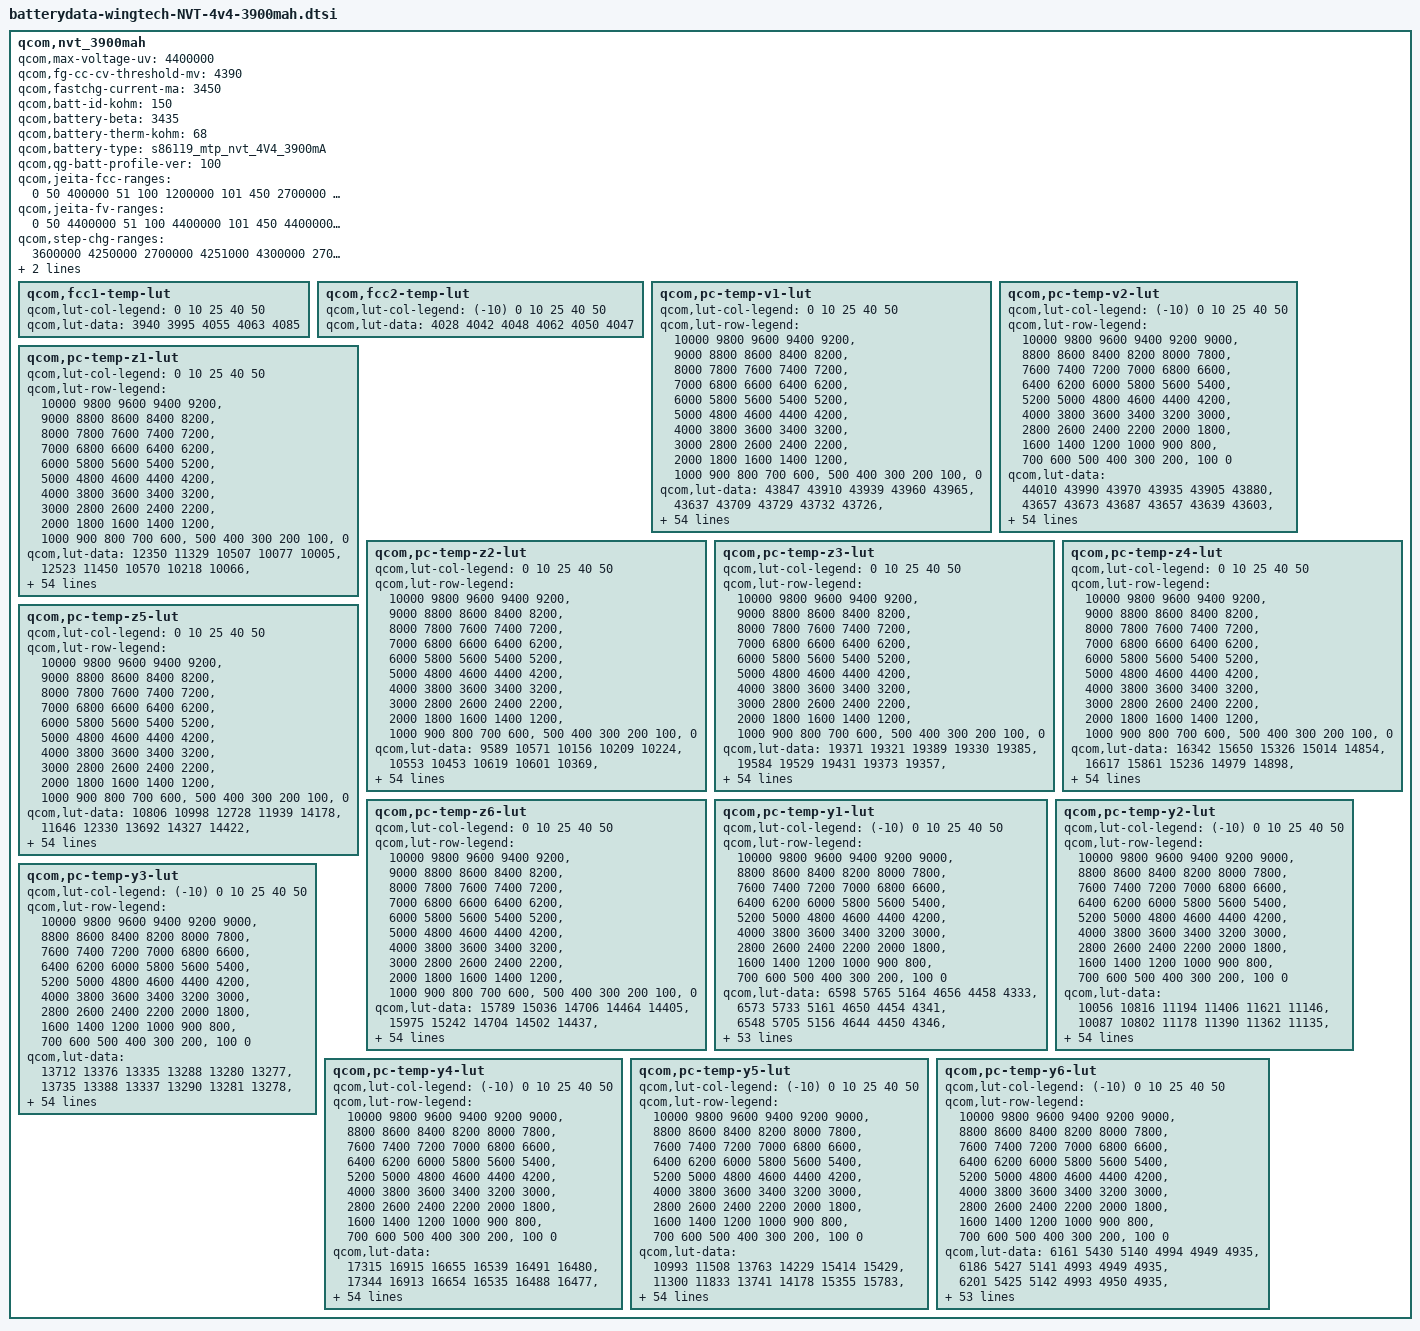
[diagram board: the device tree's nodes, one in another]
/* Copyright (c) 2018, The Linux Foundation. All rights reserved.
 *
 * This program is free software; you can redistribute it and/or modify
 * it under the terms of the GNU General Public License version 2 and
 * only version 2 as published by the Free Software Foundation.
 *
 * This program is distributed in the hope that it will be useful,
 * but WITHOUT ANY WARRANTY; without even the implied warranty of
 * MERCHANTABILITY or FITNESS FOR A PARTICULAR PURPOSE.  See the
 * GNU General Public License for more details.
 */

qcom,nvt_3900mah {
	/* nvt_wConn_3900mAh_Fresh_averaged_MasterSlave_Feb7th2018 */
	qcom,max-voltage-uv = <4400000>;
	qcom,fg-cc-cv-threshold-mv = <4390>;
	qcom,fastchg-current-ma = <3450>;
	qcom,batt-id-kohm = <150>;
	qcom,battery-beta = <3435>;
	qcom,battery-therm-kohm = <68>;
	qcom,battery-type =
		"s86119_mtp_nvt_4V4_3900mA";
	qcom,qg-batt-profile-ver = <100>;
	//+Bug 439935 gudi.wt,MODIFIY,20190628,S86119AA1 set follow to batt spec
	qcom,jeita-fcc-ranges = <0   50  400000
				51  100  1200000
				101  450 2700000
				451  600 1400000>;
	qcom,jeita-fv-ranges = <0   50  4400000
				51 100  4400000
				101 450 4400000
				451 600  4100000>;
	qcom,step-chg-ranges = <3600000  4250000  2700000
				4251000  4300000  2700000
				4301000  4400000  2700000>;

	/* COOL = 5 DegC, WARM = 45 DegC */
	qcom,jeita-soft-thresholds = <0x2E1E 0x123E>;
	/* COLD = 0 DegC, HOT = 55 DegC */
	qcom,jeita-hard-thresholds = <0x3480 0x0F3B>;
	//+Bug 439935 gudi.wt,MODIFIY,20190628,S86119AA1 set follow to batt spec
	qcom,fcc1-temp-lut {
		qcom,lut-col-legend = <0 10 25 40 50>;
		qcom,lut-data = <3940 3995 4055 4063 4085>;
	};

	qcom,fcc2-temp-lut {
		qcom,lut-col-legend = <(-10) 0 10 25 40 50>;
		qcom,lut-data = <4028 4042 4048 4062 4050 4047>;
	};

	qcom,pc-temp-v1-lut {
		qcom,lut-col-legend = <0 10 25 40 50>;
		qcom,lut-row-legend = <10000 9800 9600 9400 9200>,
			<9000 8800 8600 8400 8200>,
			<8000 7800 7600 7400 7200>,
			<7000 6800 6600 6400 6200>,
			<6000 5800 5600 5400 5200>,
			<5000 4800 4600 4400 4200>,
			<4000 3800 3600 3400 3200>,
			<3000 2800 2600 2400 2200>,
			<2000 1800 1600 1400 1200>,
			<1000 900 800 700 600>,
			<500 400 300 200 100>,
			<0>;
		qcom,lut-data = <43847 43910 43939 43960 43965>,
			<43637 43709 43729 43732 43726>,
			<43385 43471 43501 43515 43502>,
			<43131 43225 43264 43291 43283>,
			<42890 42981 43028 43058 43054>,
			<42654 42741 42790 42824 42822>,
			<42421 42505 42552 42590 42587>,
			<42189 42271 42315 42355 42351>,
			<41964 42041 42081 42121 42117>,
			<41745 41814 41849 41889 41885>,
			<41533 41589 41621 41660 41658>,
			<41334 41374 41398 41436 41437>,
			<41152 41181 41185 41218 41218>,
			<40956 40992 40988 41009 41007>,
			<40719 40777 40786 40802 40798>,
			<40474 40537 40567 40593 40588>,
			<40253 40318 40347 40388 40381>,
			<40046 40131 40155 40200 40193>,
			<39874 39961 39979 40025 40022>,
			<39743 39808 39814 39856 39856>,
			<39625 39670 39669 39702 39701>,
			<39498 39518 39512 39538 39540>,
			<39367 39347 39291 39300 39325>,
			<39231 39166 39028 39013 39048>,
			<39086 38959 38829 38830 38850>,
			<38939 38746 38674 38723 38735>,
			<38794 38604 38558 38632 38639>,
			<38651 38510 38479 38540 38543>,
			<38545 38439 38417 38454 38452>,
			<38472 38384 38356 38370 38361>,
			<38413 38339 38300 38288 38271>,
			<38363 38295 38244 38214 38189>,
			<38319 38254 38188 38148 38119>,
			<38280 38213 38134 38086 38056>,
			<38247 38172 38085 38028 38001>,
			<38214 38131 38040 37972 37952>,
			<38180 38093 37997 37919 37895>,
			<38144 38056 37958 37873 37825>,
			<38093 38005 37909 37818 37745>,
			<38012 37917 37823 37730 37655>,
			<37910 37805 37708 37617 37551>,
			<37783 37685 37583 37504 37430>,
			<37631 37547 37443 37382 37289>,
			<37470 37386 37287 37218 37137>,
			<37328 37239 37147 37068 37002>,
			<37230 37152 37066 36971 36924>,
			<37201 37126 37045 36956 36897>,
			<37174 37114 37031 36943 36892>,
			<37148 37093 37011 36932 36871>,
			<37095 37043 36941 36844 36767>,
			<36841 36791 36666 36582 36468>,
			<36394 36349 36217 36129 36013>,
			<35801 35769 35627 35601 35425>,
			<34988 34972 34817 34781 34622>,
			<33711 33731 33549 33515 33376>,
			<30000 30000 30000 30000 30000>;
	};

	qcom,pc-temp-v2-lut {
		qcom,lut-col-legend = <(-10) 0 10 25 40 50>;
		qcom,lut-row-legend = <10000 9800 9600 9400 9200 9000>,
			<8800 8600 8400 8200 8000 7800>,
			<7600 7400 7200 7000 6800 6600>,
			<6400 6200 6000 5800 5600 5400>,
			<5200 5000 4800 4600 4400 4200>,
			<4000 3800 3600 3400 3200 3000>,
			<2800 2600 2400 2200 2000 1800>,
			<1600 1400 1200 1000 900 800>,
			<700 600 500 400 300 200>,
			<100 0>;
		qcom,lut-data = <44010 43990 43970 43935 43905 43880>,
			<43657 43673 43687 43657 43639 43603>,
			<43328 43377 43418 43392 43382 43340>,
			<43029 43105 43162 43141 43138 43092>,
			<42754 42854 42919 42904 42905 42859>,
			<42489 42609 42679 42668 42672 42627>,
			<42227 42367 42442 42431 42437 42392>,
			<41973 42130 42207 42194 42202 42157>,
			<41725 41902 41976 41963 41970 41927>,
			<41485 41679 41747 41733 41741 41698>,
			<41270 41458 41522 41506 41515 41472>,
			<41085 41240 41299 41280 41293 41251>,
			<40900 41030 41085 41063 41076 41033>,
			<40704 40846 40896 40864 40870 40823>,
			<40490 40665 40712 40670 40667 40618>,
			<40205 40418 40496 40459 40461 40417>,
			<39805 40082 40246 40234 40252 40221>,
			<39500 39792 40004 40033 40059 40036>,
			<39353 39583 39782 39869 39892 39868>,
			<39236 39403 39571 39706 39729 39702>,
			<39086 39235 39371 39504 39547 39524>,
			<38916 39081 39182 39280 39352 39336>,
			<38752 38931 39009 39074 39151 39139>,
			<38588 38779 38846 38878 38934 38922>,
			<38440 38634 38699 38710 38743 38731>,
			<38322 38504 38570 38578 38606 38594>,
			<38222 38382 38452 38465 38492 38482>,
			<38139 38271 38347 38362 38388 38377>,
			<38071 38168 38253 38268 38293 38282>,
			<38010 38075 38164 38180 38206 38193>,
			<37952 37990 38079 38100 38127 38113>,
			<37897 37916 37999 38026 38054 38039>,
			<37841 37864 37922 37959 37986 37972>,
			<37782 37824 37848 37896 37923 37909>,
			<37725 37785 37793 37837 37854 37836>,
			<37669 37745 37756 37781 37774 37738>,
			<37613 37704 37720 37721 37688 37635>,
			<37554 37660 37679 37650 37593 37531>,
			<37492 37610 37635 37573 37495 37429>,
			<37430 37551 37572 37496 37409 37339>,
			<37367 37476 37479 37415 37334 37261>,
			<37306 37377 37376 37314 37238 37164>,
			<37239 37246 37256 37193 37117 37045>,
			<37145 37114 37107 37047 36980 36905>,
			<37055 36997 36976 36923 36857 36803>,
			<36947 36925 36926 36890 36828 36780>,
			<36899 36892 36902 36875 36814 36750>,
			<36847 36859 36880 36857 36795 36747>,
			<36764 36811 36844 36812 36756 36698>,
			<36640 36705 36751 36693 36643 36574>,
			<36405 36432 36461 36347 36318 36214>,
			<36008 35945 35955 35822 35827 35702>,
			<35418 35282 35293 35132 35165 35046>,
			<34556 34348 34377 34166 34287 34117>,
			<33099 32790 32996 32738 33050 32805>,
			<29158 30446 29275 28278 29363 29146>;
	};

	qcom,pc-temp-z1-lut {
		qcom,lut-col-legend = <0 10 25 40 50>;
		qcom,lut-row-legend = <10000 9800 9600 9400 9200>,
			<9000 8800 8600 8400 8200>,
			<8000 7800 7600 7400 7200>,
			<7000 6800 6600 6400 6200>,
			<6000 5800 5600 5400 5200>,
			<5000 4800 4600 4400 4200>,
			<4000 3800 3600 3400 3200>,
			<3000 2800 2600 2400 2200>,
			<2000 1800 1600 1400 1200>,
			<1000 900 800 700 600>,
			<500 400 300 200 100>,
			<0>;
		qcom,lut-data = <12350 11329 10507 10077 10005>,
			<12523 11450 10570 10218 10066>,
			<12574 11459 10576 10225 10073>,
			<12594 11473 10571 10224 10071>,
			<12583 11476 10564 10223 10070>,
			<12563 11457 10557 10220 10070>,
			<12548 11436 10549 10215 10067>,
			<12529 11425 10543 10213 10064>,
			<12515 11416 10539 10212 10071>,
			<12524 11414 10535 10212 10082>,
			<12538 11414 10533 10211 10079>,
			<12531 11414 10531 10209 10065>,
			<12510 11416 10531 10207 10059>,
			<12490 11419 10532 10205 10061>,
			<12463 11410 10532 10203 10066>,
			<12437 11374 10525 10202 10085>,
			<12423 11353 10516 10201 10115>,
			<12398 11349 10515 10200 10117>,
			<12380 11347 10515 10200 10084>,
			<12389 11349 10516 10201 10064>,
			<12401 11353 10518 10202 10066>,
			<12390 11355 10520 10203 10072>,
			<12366 11358 10522 10205 10083>,
			<12356 11363 10523 10208 10104>,
			<12359 11370 10525 10210 10111>,
			<12366 11380 10527 10212 10100>,
			<12384 11390 10530 10213 10091>,
			<12421 11406 10537 10216 10094>,
			<12433 11416 10544 10219 10099>,
			<12414 11408 10546 10222 10098>,
			<12395 11394 10546 10225 10088>,
			<12405 11392 10546 10228 10084>,
			<12435 11397 10551 10228 10091>,
			<12446 11403 10557 10229 10100>,
			<12437 11412 10563 10231 10100>,
			<12428 11421 10568 10235 10096>,
			<12430 11422 10574 10237 10096>,
			<12435 11423 10579 10238 10098>,
			<12436 11424 10584 10240 10100>,
			<12424 11423 10589 10276 10101>,
			<12416 11422 10595 10330 10101>,
			<12446 11431 10599 10320 10103>,
			<12481 11448 10603 10258 10105>,
			<12442 11465 10614 10305 10107>,
			<12388 11474 10622 10360 10110>,
			<12370 11446 10620 10278 10112>,
			<12355 11466 10614 10271 10139>,
			<12354 11447 10616 10316 10126>,
			<12414 11438 10617 10279 10110>,
			<12340 11477 10619 10325 10114>,
			<12419 11464 10631 10281 10116>,
			<12407 11501 10641 10347 10123>,
			<12407 11505 10655 10333 10131>,
			<12468 11544 10684 10374 10145>,
			<12468 11544 10684 10374 10145>,
			<12468 11544 10684 10374 10145>;
	};

	qcom,pc-temp-z2-lut {
		qcom,lut-col-legend = <0 10 25 40 50>;
		qcom,lut-row-legend = <10000 9800 9600 9400 9200>,
			<9000 8800 8600 8400 8200>,
			<8000 7800 7600 7400 7200>,
			<7000 6800 6600 6400 6200>,
			<6000 5800 5600 5400 5200>,
			<5000 4800 4600 4400 4200>,
			<4000 3800 3600 3400 3200>,
			<3000 2800 2600 2400 2200>,
			<2000 1800 1600 1400 1200>,
			<1000 900 800 700 600>,
			<500 400 300 200 100>,
			<0>;
		qcom,lut-data = <9589 10571 10156 10209 10224>,
			<10553 10453 10619 10601 10369>,
			<10385 10412 10597 10658 10566>,
			<10262 10358 10553 10628 10557>,
			<10259 10324 10493 10579 10498>,
			<10257 10302 10459 10567 10475>,
			<10259 10290 10435 10565 10477>,
			<10271 10288 10429 10567 10482>,
			<10285 10287 10462 10573 10497>,
			<10295 10288 10501 10580 10518>,
			<10305 10296 10520 10594 10500>,
			<10332 10309 10535 10613 10422>,
			<10394 10351 10551 10621 10392>,
			<10426 10403 10570 10623 10422>,
			<10361 10406 10580 10624 10440>,
			<10274 10388 10567 10619 10445>,
			<10270 10380 10550 10608 10454>,
			<10311 10423 10548 10596 10448>,
			<10366 10473 10550 10570 10376>,
			<10472 10474 10555 10550 10338>,
			<10570 10464 10585 10546 10372>,
			<10557 10460 10636 10568 10433>,
			<10472 10464 10724 10697 10547>,
			<10417 10471 10835 10928 10753>,
			<10395 10483 10854 10960 10823>,
			<10383 10498 10809 10701 10608>,
			<10385 10502 10754 10510 10405>,
			<10392 10500 10695 10553 10431>,
			<10399 10499 10645 10636 10519>,
			<10405 10501 10666 10717 10616>,
			<10412 10508 10765 10881 10752>,
			<10421 10518 10813 10947 10816>,
			<10432 10533 10818 10825 10710>,
			<10445 10540 10820 10697 10557>,
			<10460 10539 10788 10703 10510>,
			<10477 10537 10717 10741 10518>,
			<10503 10540 10700 10779 10580>,
			<10536 10550 10713 10827 10810>,
			<10566 10564 10735 10867 10980>,
			<10593 10584 10796 10896 10960>,
			<10624 10609 10870 10915 10917>,
			<10667 10636 10881 10919 10892>,
			<10738 10671 10873 10940 10872>,
			<10955 10738 10893 11031 10816>,
			<11280 10967 10987 11103 10707>,
			<11381 11436 11144 10782 10627>,
			<10891 11588 11094 10741 10570>,
			<10873 11637 11063 10722 10690>,
			<10876 11891 11118 11007 10736>,
			<10917 11547 11211 10889 10675>,
			<10931 11771 11325 11573 10558>,
			<10619 11757 11302 10939 10316>,
			<10625 11425 11226 11470 10305>,
			<10335 10897 11033 10507 10251>,
			<10335 10897 11033 10507 10251>,
			<10335 10897 11033 10507 10251>;
	};

	qcom,pc-temp-z3-lut {
		qcom,lut-col-legend = <0 10 25 40 50>;
		qcom,lut-row-legend = <10000 9800 9600 9400 9200>,
			<9000 8800 8600 8400 8200>,
			<8000 7800 7600 7400 7200>,
			<7000 6800 6600 6400 6200>,
			<6000 5800 5600 5400 5200>,
			<5000 4800 4600 4400 4200>,
			<4000 3800 3600 3400 3200>,
			<3000 2800 2600 2400 2200>,
			<2000 1800 1600 1400 1200>,
			<1000 900 800 700 600>,
			<500 400 300 200 100>,
			<0>;
		qcom,lut-data = <19371 19321 19389 19330 19385>,
			<19584 19529 19431 19373 19357>,
			<19829 19667 19526 19436 19403>,
			<19963 19743 19568 19472 19445>,
			<19983 19779 19587 19493 19460>,
			<19994 19800 19589 19494 19462>,
			<19994 19811 19588 19483 19454>,
			<19990 19813 19585 19472 19446>,
			<19983 19814 19570 19463 19446>,
			<19963 19813 19550 19455 19447>,
			<19935 19806 19534 19445 19437>,
			<19907 19793 19519 19435 19408>,
			<19867 19756 19505 19425 19394>,
			<19847 19713 19490 19417 19393>,
			<19945 19708 19483 19410 19393>,
			<20074 19712 19485 19404 19392>,
			<20083 19713 19490 19399 19392>,
			<20046 19689 19487 19393 19389>,
			<19995 19660 19474 19387 19364>,
			<19881 19656 19465 19380 19347>,
			<19769 19655 19459 19372 19346>,
			<19779 19656 19455 19366 19346>,
			<19868 19679 19472 19379 19355>,
			<19941 19706 19508 19411 19379>,
			<19988 19719 19516 19417 19388>,
			<20022 19729 19506 19393 19365>,
			<20035 19731 19491 19369 19338>,
			<20043 19725 19474 19357 19326>,
			<20044 19717 19456 19349 19318>,
			<20032 19706 19445 19354 19325>,
			<20013 19694 19435 19382 19374>,
			<19997 19684 19433 19400 19404>,
			<19980 19674 19458 19407 19400>,
			<19961 19669 19481 19411 19393>,
			<19939 19672 19482 19408 19381>,
			<19914 19675 19481 19401 19359>,
			<19885 19672 19478 19394 19352>,
			<19852 19661 19469 19388 19361>,
			<19830 19652 19460 19384 19367>,
			<19813 19648 19452 19389 19365>,
			<19796 19643 19446 19397 19361>,
			<19774 19630 19444 19387 19362>,
			<19737 19608 19443 19350 19367>,
			<19653 19583 19437 19353 19365>,
			<19481 19531 19419 19359 19352>,
			<19353 19440 19386 19344 19337>,
			<19320 19415 19380 19344 19333>,
			<19316 19320 19365 19334 19310>,
			<19314 19308 19362 19310 19308>,
			<19311 19297 19347 19327 19316>,
			<19320 19332 19322 19292 19320>,
			<19314 19333 19310 19331 19334>,
			<19326 19321 19316 19293 19333>,
			<19333 19313 19311 19340 19336>,
			<19333 19313 19311 19340 19336>,
			<19333 19313 19311 19340 19336>;
	};

	qcom,pc-temp-z4-lut {
		qcom,lut-col-legend = <0 10 25 40 50>;
		qcom,lut-row-legend = <10000 9800 9600 9400 9200>,
			<9000 8800 8600 8400 8200>,
			<8000 7800 7600 7400 7200>,
			<7000 6800 6600 6400 6200>,
			<6000 5800 5600 5400 5200>,
			<5000 4800 4600 4400 4200>,
			<4000 3800 3600 3400 3200>,
			<3000 2800 2600 2400 2200>,
			<2000 1800 1600 1400 1200>,
			<1000 900 800 700 600>,
			<500 400 300 200 100>,
			<0>;
		qcom,lut-data = <16342 15650 15326 15014 14854>,
			<16617 15861 15236 14979 14898>,
			<16518 15839 15335 15046 14877>,
			<16385 15659 15272 15018 14935>,
			<16227 15508 15158 14943 14876>,
			<16049 15388 15089 14891 14832>,
			<15906 15286 15039 14848 14801>,
			<15779 15205 14992 14826 14783>,
			<15691 15137 14941 14818 14780>,
			<15643 15082 14904 14813 14777>,
			<15607 15035 14894 14807 14775>,
			<15570 14998 14888 14800 14773>,
			<15521 14964 14879 14793 14771>,
			<15461 14937 14865 14783 14753>,
			<15332 14931 14849 14773 14737>,
			<15203 14929 14834 14765 14739>,
			<15191 14928 14818 14757 14742>,
			<15205 14928 14803 14747 14739>,
			<15211 14928 14787 14733 14731>,
			<15242 14911 14776 14727 14724>,
			<15279 14866 14765 14729 14717>,
			<15237 14835 14757 14733 14712>,
			<15090 14816 14776 14762 14730>,
			<14981 14806 14828 14830 14805>,
			<14923 14835 14870 14868 14854>,
			<14888 14902 14909 14887 14876>,
			<14894 14925 14928 14895 14888>,
			<14915 14929 14927 14892 14890>,
			<14925 14930 14925 14885 14885>,
			<14926 14923 14920 14867 14863>,
			<14927 14908 14906 14818 14782>,
			<14923 14893 14887 14777 14728>,
			<14914 14878 14842 14746 14718>,
			<14906 14861 14798 14726 14713>,
			<14901 14840 14778 14724 14713>,
			<14897 14820 14764 14723 14715>,
			<14897 14808 14759 14723 14716>,
			<14902 14799 14757 14726 14718>,
			<14903 14796 14756 14731 14720>,
			<14889 14794 14770 14757 14728>,
			<14877 14794 14790 14792 14740>,
			<14874 14793 14790 14792 14739>,
			<14875 14792 14780 14772 14729>,
			<14914 14789 14776 14784 14731>,
			<14945 14773 14764 14793 14734>,
			<14969 14765 14725 14732 14705>,
			<14995 14785 14717 14713 14711>,
			<14991 14881 14713 14714 14702>,
			<14987 14888 14697 14699 14668>,
			<14983 14896 14718 14713 14672>,
			<14988 14875 14785 14758 14703>,
			<15010 14885 14811 14759 14696>,
			<15007 14909 14809 14750 14698>,
			<15020 14929 14822 14734 14696>,
			<15020 14929 14822 14734 14696>,
			<15020 14929 14822 14734 14696>;
	};

	qcom,pc-temp-z5-lut {
		qcom,lut-col-legend = <0 10 25 40 50>;
		qcom,lut-row-legend = <10000 9800 9600 9400 9200>,
			<9000 8800 8600 8400 8200>,
			<8000 7800 7600 7400 7200>,
			<7000 6800 6600 6400 6200>,
			<6000 5800 5600 5400 5200>,
			<5000 4800 4600 4400 4200>,
			<4000 3800 3600 3400 3200>,
			<3000 2800 2600 2400 2200>,
			<2000 1800 1600 1400 1200>,
			<1000 900 800 700 600>,
			<500 400 300 200 100>,
			<0>;
		qcom,lut-data = <10806 10998 12728 11939 14178>,
			<11646 12330 13692 14327 14422>,
			<12442 13290 14476 15377 16936>,
			<12922 13882 14876 15857 16779>,
			<13057 14353 15220 16882 17794>,
			<13146 14736 15411 17476 18632>,
			<13270 15109 15540 17900 19328>,
			<13477 15542 15756 18058 19697>,
			<13590 16005 16360 17928 19582>,
			<13497 16507 16856 17734 19310>,
			<13377 17141 16753 17550 18845>,
			<13353 17534 16473 17291 17690>,
			<13311 17612 16389 17221 17320>,
			<13436 17671 16403 17274 18721>,
			<15411 18037 16444 17327 19875>,
			<17756 18957 16868 17356 19824>,
			<17898 19370 17569 17394 19699>,
			<17356 18135 18079 17591 19089>,
			<16754 16688 18780 18202 17702>,
			<15692 16921 19424 18602 16933>,
			<14686 18449 20567 18648 17373>,
			<15055 20978 22708 18854 18522>,
			<17128 28139 31386 23602 21655>,
			<20088 35878 45887 33994 28548>,
			<25891 40453 48473 36008 30908>,
			<32633 43967 41165 27497 24444>,
			<37727 44260 33355 19881 17460>,
			<42200 39970 27930 17383 15423>,
			<43440 35014 23506 15891 14245>,
			<40999 31484 20907 15961 14626>,
			<37635 28467 19022 17225 18304>,
			<35337 26657 18541 18845 21520>,
			<33310 25311 20596 21135 23066>,
			<31282 24789 23526 23614 24084>,
			<29194 25974 25958 25761 23804>,
			<27179 27538 28180 27689 22157>,
			<25022 27583 28620 28068 22090>,
			<22864 27090 28117 27286 25307>,
			<22011 26913 27402 26039 27757>,
			<22340 28089 25940 23750 25329>,
			<22776 29335 24187 20812 21092>,
			<22493 28068 23507 18811 20474>,
			<21530 25083 23098 17245 21027>,
			<19009 24057 22034 17268 20180>,
			<15964 23419 21397 17595 18117>,
			<13972 19974 21297 22901 17679>,
			<13115 17339 20079 21157 18804>,
			<12998 13243 18091 19247 16348>,
			<12975 12808 18590 16465 17382>,
			<12988 12647 16821 20918 17667>,
			<13210 13642 13935 13711 14742>,
			<12918 13442 12983 13661 15010>,
			<12967 12913 12951 12368 14621>,
			<12819 12554 12603 18035 14421>,
			<12819 12554 12603 18035 14421>,
			<12819 12554 12603 18035 14421>;
	};

	qcom,pc-temp-z6-lut {
		qcom,lut-col-legend = <0 10 25 40 50>;
		qcom,lut-row-legend = <10000 9800 9600 9400 9200>,
			<9000 8800 8600 8400 8200>,
			<8000 7800 7600 7400 7200>,
			<7000 6800 6600 6400 6200>,
			<6000 5800 5600 5400 5200>,
			<5000 4800 4600 4400 4200>,
			<4000 3800 3600 3400 3200>,
			<3000 2800 2600 2400 2200>,
			<2000 1800 1600 1400 1200>,
			<1000 900 800 700 600>,
			<500 400 300 200 100>,
			<0>;
		qcom,lut-data = <15789 15036 14706 14464 14405>,
			<15975 15242 14704 14502 14437>,
			<16026 15270 14795 14566 14452>,
			<16043 15237 14782 14566 14496>,
			<15994 15200 14750 14551 14483>,
			<15899 15154 14725 14534 14468>,
			<15825 15109 14701 14509 14450>,
			<15757 15073 14675 14491 14437>,
			<15704 15040 14645 14483 14437>,
			<15671 15012 14619 14477 14438>,
			<15644 14988 14606 14468 14432>,
			<15603 14964 14596 14459 14414>,
			<15545 14929 14584 14451 14402>,
			<15512 14897 14571 14442 14394>,
			<15508 14886 14559 14433 14388>,
			<15507 14882 14553 14426 14389>,
			<15500 14877 14547 14419 14396>,
			<15482 14865 14538 14411 14392>,
			<15456 14851 14524 14401 14370>,
			<15410 14834 14514 14395 14354>,
			<15362 14816 14505 14391 14351>,
			<15340 14811 14501 14389 14350>,
			<15326 14815 14518 14409 14364>,
			<15322 14822 14560 14459 14415>,
			<15323 14844 14580 14473 14436>,
			<15327 14881 14590 14468 14431>,
			<15336 14892 14594 14462 14423>,
			<15354 14892 14588 14456 14418>,
			<15360 14891 14577 14449 14413>,
			<15355 14883 14568 14443 14407>,
			<15347 14869 14557 14437 14397>,
			<15337 14857 14549 14431 14389>,
			<15323 14848 14543 14422 14384>,
			<15311 14839 14537 14415 14380>,
			<15298 14832 14531 14410 14373>,
			<15286 14825 14525 14407 14361>,
			<15278 14818 14520 14405 14358>,
			<15270 14812 14514 14403 14362>,
			<15260 14808 14511 14402 14366>,
			<15248 14806 14515 14420 14369>,
			<15234 14804 14519 14449 14371>,
			<15221 14800 14519 14442 14371>,
			<15203 14794 14515 14404 14370>,
			<15176 14783 14511 14418 14369>,
			<15103 14753 14499 14434 14365>,
			<15053 14701 14465 14385 14344>,
			<15036 14697 14458 14376 14349>,
			<15035 14692 14448 14379 14330>,
			<15033 14690 14440 14353 14312>,
			<15032 14692 14442 14376 14318>,
			<15054 14705 14458 14371 14336>,
			<15057 14716 14467 14403 14343>,
			<15072 14729 14472 14378 14345>,
			<15112 14746 14483 14402 14350>,
			<15112 14746 14483 14402 14350>,
			<15112 14746 14483 14402 14350>;
	};

	qcom,pc-temp-y1-lut {
		qcom,lut-col-legend = <(-10) 0 10 25 40 50>;
		qcom,lut-row-legend = <10000 9800 9600 9400 9200 9000>,
			<8800 8600 8400 8200 8000 7800>,
			<7600 7400 7200 7000 6800 6600>,
			<6400 6200 6000 5800 5600 5400>,
			<5200 5000 4800 4600 4400 4200>,
			<4000 3800 3600 3400 3200 3000>,
			<2800 2600 2400 2200 2000 1800>,
			<1600 1400 1200 1000 900 800>,
			<700 600 500 400 300 200>,
			<100 0>;
		qcom,lut-data = <6598 5765 5164 4656 4458 4333>,
			<6573 5733 5161 4650 4454 4341>,
			<6548 5705 5156 4644 4450 4346>,
			<6524 5682 5148 4639 4445 4350>,
			<6505 5667 5141 4634 4441 4351>,
			<6496 5663 5136 4630 4439 4351>,
			<6508 5671 5130 4628 4438 4348>,
			<6524 5681 5125 4625 4438 4345>,
			<6516 5688 5120 4622 4437 4346>,
			<6496 5696 5110 4619 4435 4348>,
			<6492 5695 5105 4616 4433 4349>,
			<6507 5664 5099 4614 4431 4345>,
			<6518 5640 5093 4612 4429 4342>,
			<6522 5651 5092 4610 4431 4343>,
			<6533 5669 5091 4609 4434 4344>,
			<6533 5668 5090 4610 4433 4346>,
			<6511 5647 5087 4612 4427 4347>,
			<6500 5635 5085 4614 4425 4348>,
			<6540 5656 5088 4612 4427 4346>,
			<6588 5684 5091 4610 4429 4345>,
			<6575 5686 5091 4611 4430 4345>,
			<6514 5672 5092 4613 4431 4347>,
			<6489 5664 5095 4615 4432 4348>,
			<6498 5661 5104 4618 4434 4349>,
			<6506 5659 5110 4621 4434 4350>,
			<6505 5656 5105 4622 4435 4351>,
			<6500 5651 5096 4624 4436 4353>,
			<6493 5651 5096 4627 4436 4354>,
			<6480 5649 5105 4635 4437 4358>,
			<6469 5647 5110 4639 4439 4360>,
			<6456 5644 5110 4640 4441 4360>,
			<6442 5645 5110 4640 4444 4360>,
			<6453 5658 5118 4642 4447 4362>,
			<6494 5677 5139 4646 4450 4365>,
			<6510 5684 5146 4652 4452 4367>,
			<6488 5664 5136 4660 4454 4370>,
			<6461 5645 5127 4667 4456 4372>,
			<6446 5648 5131 4668 4457 4373>,
			<6433 5660 5140 4670 4458 4374>,
			<6432 5673 5146 4673 4459 4375>,
			<6468 5689 5151 4677 4460 4376>,
			<6484 5681 5158 4677 4461 4377>,
			<6443 5646 5175 4676 4463 4379>,
			<6443 5691 5162 4681 4467 4380>,
			<6450 5676 5177 4691 4467 4397>,
			<6517 5697 5188 4698 4469 4385>,
			<6446 5728 5200 4693 4469 4414>,
			<6461 5710 5196 4697 4472 4398>,
			<6512 5687 5203 4700 4473 4385>,
			<6492 5696 5216 4706 4473 4386>,
			<6493 5676 5214 4701 4474 4390>,
			<6472 5702 5201 4712 4528 4420>,
			<6503 5698 5247 4738 4489 4400>,
			<6603 5705 5251 4751 4547 4413>,
			<6603 5705 5251 4751 4547 4413>,
			<6603 5705 5251 4751 4547 4413>;
	};

	qcom,pc-temp-y2-lut {
		qcom,lut-col-legend = <(-10) 0 10 25 40 50>;
		qcom,lut-row-legend = <10000 9800 9600 9400 9200 9000>,
			<8800 8600 8400 8200 8000 7800>,
			<7600 7400 7200 7000 6800 6600>,
			<6400 6200 6000 5800 5600 5400>,
			<5200 5000 4800 4600 4400 4200>,
			<4000 3800 3600 3400 3200 3000>,
			<2800 2600 2400 2200 2000 1800>,
			<1600 1400 1200 1000 900 800>,
			<700 600 500 400 300 200>,
			<100 0>;
		qcom,lut-data = <10056 10816 11194 11406 11621 11146>,
			<10087 10802 11178 11390 11362 11135>,
			<10119 10779 11147 11374 11183 11111>,
			<10148 10755 11111 11359 11070 11085>,
			<10168 10737 11084 11344 11007 11064>,
			<10175 10730 11075 11330 10984 11058>,
			<10169 10729 11076 11317 11044 11059>,
			<10161 10730 11078 11304 11113 11060>,
			<10200 10736 11079 11283 11133 11068>,
			<10319 10748 11081 11259 11175 11085>,
			<10417 10748 11080 11258 11190 11092>,
			<10497 10715 11071 11299 11199 11094>,
			<10559 10689 11059 11326 11211 11092>,
			<10590 10780 11029 11307 11223 11115>,
			<10614 10933 10992 11277 11239 11155>,
			<10668 10959 11005 11304 11268 11163>,
			<10789 10954 11087 11425 11327 11168>,
			<10910 10951 11131 11489 11380 11187>,
			<11024 10978 11132 11503 11420 11250>,
			<11109 11019 11133 11509 11465 11342>,
			<11118 11050 11151 11497 11545 11456>,
			<11118 11077 11204 11468 11662 11592>,
			<11080 11109 11252 11453 11672 11607>,
			<10412 11148 11295 11449 11441 11355>,
			<9746 11192 11333 11453 11259 11152>,
			<9693 11246 11375 11484 11291 11218>,
			<9680 11300 11413 11526 11351 11348>,
			<9676 11315 11415 11538 11354 11395>,
			<9673 11318 11395 11536 11297 11384>,
			<9671 11323 11382 11540 11271 11377>,
			<9669 11378 11379 11556 11419 11404>,
			<9667 11446 11377 11575 11610 11444>,
			<9665 11426 11391 11595 11675 11503>,
			<9664 11327 11432 11615 11740 11592>,
			<9662 11249 11443 11617 11739 11615>,
			<9661 11201 11399 11600 11658 11492>,
			<9659 11159 11341 11579 11557 11345>,
			<9658 11124 11294 11558 11445 11253>,
			<9658 11091 11253 11533 11323 11173>,
			<9657 11044 11232 11487 11283 11144>,
			<9656 10971 11219 11409 11333 11132>,
			<9656 10901 11191 11403 11292 11167>,
			<9656 10837 11142 11398 11278 11283>,
			<9656 10781 11154 11442 11458 11100>,
			<9656 10503 11234 11366 11110 11139>,
			<9655 9730 11057 11311 11208 11187>,
			<9655 9688 11054 11325 11120 10726>,
			<9655 9680 10993 11268 11108 11454>,
			<9654 9673 10868 11227 11022 11102>,
			<9654 9668 10836 11167 10987 10853>,
			<9654 9663 10764 11164 10946 11058>,
			<9653 9659 10620 11109 10718 10703>,
			<9652 9656 10507 11027 10744 10616>,
			<9650 9654 10414 10847 10821 10952>,
			<9650 9654 10414 10847 10821 10952>,
			<9650 9654 10414 10847 10821 10952>;
	};

	qcom,pc-temp-y3-lut {
		qcom,lut-col-legend = <(-10) 0 10 25 40 50>;
		qcom,lut-row-legend = <10000 9800 9600 9400 9200 9000>,
			<8800 8600 8400 8200 8000 7800>,
			<7600 7400 7200 7000 6800 6600>,
			<6400 6200 6000 5800 5600 5400>,
			<5200 5000 4800 4600 4400 4200>,
			<4000 3800 3600 3400 3200 3000>,
			<2800 2600 2400 2200 2000 1800>,
			<1600 1400 1200 1000 900 800>,
			<700 600 500 400 300 200>,
			<100 0>;
		qcom,lut-data = <13712 13376 13335 13288 13280 13277>,
			<13735 13388 13337 13290 13281 13278>,
			<13747 13401 13339 13292 13282 13279>,
			<13751 13413 13340 13294 13283 13280>,
			<13750 13423 13341 13296 13284 13281>,
			<13746 13430 13341 13298 13285 13283>,
			<13723 13435 13342 13299 13286 13285>,
			<13700 13438 13342 13299 13287 13286>,
			<13723 13442 13342 13301 13288 13287>,
			<13787 13446 13341 13304 13289 13288>,
			<13793 13451 13341 13304 13290 13289>,
			<13627 13461 13344 13306 13295 13290>,
			<13492 13468 13348 13308 13299 13290>,
			<13537 13468 13360 13311 13298 13290>,
			<13623 13467 13375 13313 13297 13289>,
			<13623 13463 13379 13312 13296 13290>,
			<13525 13449 13380 13308 13296 13293>,
			<13466 13435 13381 13307 13296 13295>,
			<13478 13420 13375 13311 13295 13294>,
			<13493 13408 13367 13315 13294 13294>,
			<13486 13405 13359 13314 13295 13294>,
			<13455 13403 13350 13310 13295 13294>,
			<13435 13401 13343 13306 13294 13293>,
			<13429 13394 13337 13298 13287 13284>,
			<13424 13386 13333 13294 13280 13278>,
			<13415 13377 13329 13293 13280 13278>,
			<13404 13368 13327 13293 13280 13279>,
			<13403 13365 13327 13293 13280 13279>,
			<13411 13364 13332 13295 13280 13278>,
			<13424 13362 13335 13297 13280 13278>,
			<13439 13351 13336 13298 13281 13277>,
			<13460 13337 13335 13299 13283 13277>,
			<13482 13340 13333 13299 13285 13278>,
			<13507 13357 13329 13299 13287 13279>,
			<13537 13368 13327 13300 13288 13280>,
			<13583 13374 13334 13302 13286 13279>,
			<13639 13379 13340 13304 13284 13277>,
			<13699 13384 13344 13302 13282 13276>,
			<13765 13391 13347 13299 13280 13276>,
			<13834 13396 13347 13297 13280 13276>,
			<13909 13401 13341 13297 13280 13276>,
			<13994 13401 13338 13295 13280 13277>,
			<14069 13393 13337 13295 13279 13279>,
			<14048 13374 13326 13291 13280 13278>,
			<13951 13359 13311 13292 13281 13284>,
			<14123 13398 13327 13296 13286 13294>,
			<14212 13421 13325 13299 13289 13289>,
			<14308 13447 13333 13304 13293 13317>,
			<14396 13482 13344 13305 13293 13299>,
			<14502 13535 13360 13312 13293 13292>,
			<14619 13594 13352 13304 13289 13309>,
			<14766 13704 13352 13307 13299 13304>,
			<15053 13933 13378 13320 13293 13289>,
			<15880 14285 13420 13342 13327 13323>,
			<15880 14285 13420 13342 13327 13323>,
			<15880 14285 13420 13342 13327 13323>;
	};

	qcom,pc-temp-y4-lut {
		qcom,lut-col-legend = <(-10) 0 10 25 40 50>;
		qcom,lut-row-legend = <10000 9800 9600 9400 9200 9000>,
			<8800 8600 8400 8200 8000 7800>,
			<7600 7400 7200 7000 6800 6600>,
			<6400 6200 6000 5800 5600 5400>,
			<5200 5000 4800 4600 4400 4200>,
			<4000 3800 3600 3400 3200 3000>,
			<2800 2600 2400 2200 2000 1800>,
			<1600 1400 1200 1000 900 800>,
			<700 600 500 400 300 200>,
			<100 0>;
		qcom,lut-data = <17315 16915 16655 16539 16491 16480>,
			<17344 16913 16654 16535 16488 16477>,
			<17391 16911 16655 16534 16487 16473>,
			<17442 16910 16657 16534 16487 16470>,
			<17485 16908 16661 16536 16488 16468>,
			<17507 16907 16665 16539 16488 16468>,
			<17523 16906 16671 16545 16490 16468>,
			<17534 16904 16680 16553 16494 16469>,
			<17452 16909 16694 16561 16499 16471>,
			<17242 16918 16712 16571 16506 16476>,
			<17211 16919 16728 16580 16510 16481>,
			<17626 16906 16741 16591 16512 16487>,
			<17966 16896 16754 16604 16514 16494>,
			<17837 16962 16768 16619 16526 16504>,
			<17557 17070 16781 16638 16544 16514>,
			<17386 17063 16785 16660 16558 16522>,
			<17272 16937 16787 16687 16570 16528>,
			<17197 16847 16786 16708 16584 16536>,
			<17154 16816 16748 16723 16609 16555>,
			<17123 16796 16694 16733 16630 16572>,
			<17102 16782 16660 16709 16628 16575>,
			<17085 16771 16633 16645 16616 16575>,
			<17080 16762 16619 16595 16596 16568>,
			<17083 16752 16610 16552 16541 16524>,
			<17085 16746 16606 16531 16502 16488>,
			<17082 16747 16609 16532 16499 16485>,
			<17074 16748 16614 16534 16499 16484>,
			<17072 16745 16614 16538 16501 16486>,
			<17074 16726 16612 16546 16513 16496>,
			<17075 16714 16611 16554 16526 16508>,
			<17075 16730 16614 16565 16538 16521>,
			<17074 16752 16617 16576 16549 16534>,
			<17078 16751 16619 16589 16559 16547>,
			<17091 16738 16620 16602 16568 16558>,
			<17098 16734 16622 16605 16569 16561>,
			<17099 16745 16627 16600 16559 16543>,
			<17101 16759 16635 16592 16544 16522>,
			<17109 16772 16647 16576 16524 16505>,
			<17129 16784 16660 16558 16503 16491>,
			<17151 16789 16661 16556 16500 16490>,
			<17175 16789 16656 16559 16508 16495>,
			<17190 16783 16655 16560 16510 16493>,
			<17204 16766 16655 16560 16510 16487>,
			<17202 16765 16641 16544 16504 16485>,
			<17065 16772 16629 16510 16473 16448>,
			<17083 16821 16632 16540 16492 16463>,
			<17093 16857 16666 16563 16507 16460>,
			<17106 16891 16696 16587 16519 16460>,
			<17131 16936 16736 16617 16552 16518>,
			<17149 16960 16743 16616 16551 16556>,
			<17145 16948 16730 16571 16512 16452>,
			<17128 16936 16729 16570 16457 16442>,
			<17185 16959 16736 16568 16510 16538>,
			<17575 17027 16760 16603 16470 16474>,
			<17575 17027 16760 16603 16470 16474>,
			<17575 17027 16760 16603 16470 16474>;
	};

	qcom,pc-temp-y5-lut {
		qcom,lut-col-legend = <(-10) 0 10 25 40 50>;
		qcom,lut-row-legend = <10000 9800 9600 9400 9200 9000>,
			<8800 8600 8400 8200 8000 7800>,
			<7600 7400 7200 7000 6800 6600>,
			<6400 6200 6000 5800 5600 5400>,
			<5200 5000 4800 4600 4400 4200>,
			<4000 3800 3600 3400 3200 3000>,
			<2800 2600 2400 2200 2000 1800>,
			<1600 1400 1200 1000 900 800>,
			<700 600 500 400 300 200>,
			<100 0>;
		qcom,lut-data = <10993 11508 13763 14229 15414 15429>,
			<11300 11833 13741 14178 15355 15783>,
			<11587 12192 13681 14105 15269 16151>,
			<11828 12545 13599 14014 15165 16473>,
			<11998 12852 13510 13906 15054 16693>,
			<12072 13074 13426 13781 14946 16756>,
			<12025 13240 13265 13548 14807 16700>,
			<11980 13393 13063 13307 14626 16589>,
			<12653 13567 12852 13197 14324 16361>,
			<14311 13789 12632 13165 13938 15937>,
			<14691 14045 12590 13134 13901 15510>,
			<12968 14390 12719 12988 14420 15069>,
			<11557 14684 12933 12884 14801 14608>,
			<14159 14829 13354 12834 14352 14026>,
			<18923 14955 14101 12774 13573 13509>,
			<19113 15419 15284 12743 13258 13496>,
			<14692 16704 17311 12717 13102 13772>,
			<12053 17317 18568 12769 13047 13909>,
			<13000 16167 19082 13988 13006 13765>,
			<14229 14834 19374 15667 13079 13604>,
			<14322 14891 18901 16963 14146 14285>,
			<14106 15360 17437 18102 16401 16120>,
			<13769 15511 16366 18149 17019 16665>,
			<12964 15286 15649 16699 16245 16069>,
			<12157 14958 15142 15544 15515 15596>,
			<11790 14555 14814 15249 15221 15618>,
			<11545 14142 14588 15081 14957 15664>,
			<11487 14104 14752 15166 14772 15515>,
			<11480 14338 15693 15591 14506 14739>,
			<11477 14474 16346 15924 14390 14214>,
			<11509 13689 16601 16098 14633 14083>,
			<11573 12650 16765 16267 15110 14068>,
			<11555 12813 16452 16482 15888 14339>,
			<11446 13748 15554 16788 17024 14979>,
			<11394 14303 15323 17358 17404 15402>,
			<11431 14583 16136 18644 17373 15671>,
			<11476 14791 16859 19392 17274 15822>,
			<11459 15066 17081 18490 16711 15801>,
			<11367 15487 17286 16924 15712 15693>,
			<11311 15737 17008 15964 15207 15407>,
			<11320 15992 15653 15252 14958 14720>,
			<11415 15832 14822 14525 14373 14737>,
			<11567 14681 14414 14265 13795 15083>,
			<11331 13137 13498 14278 14453 15193>,
			<11663 12176 12429 14947 16221 28272>,
			<11689 12029 13101 13796 14789 56722>,
			<11926 11866 12583 13356 14100 54301>,
			<12170 11979 12693 13354 14466 65535>,
			<12098 12060 12798 12936 13933 44994>,
			<12292 12359 13536 13698 13958 15862>,
			<12228 12359 13041 13357 14023 65535>,
			<11981 12105 12580 13629 65535 65535>,
			<11502 12169 13392 15151 22065 26844>,
			<10658 12167 14941 18622 49778 65535>,
			<10658 12167 14941 18622 49778 65535>,
			<10658 12167 14941 18622 49778 65535>;
	};

	qcom,pc-temp-y6-lut {
		qcom,lut-col-legend = <(-10) 0 10 25 40 50>;
		qcom,lut-row-legend = <10000 9800 9600 9400 9200 9000>,
			<8800 8600 8400 8200 8000 7800>,
			<7600 7400 7200 7000 6800 6600>,
			<6400 6200 6000 5800 5600 5400>,
			<5200 5000 4800 4600 4400 4200>,
			<4000 3800 3600 3400 3200 3000>,
			<2800 2600 2400 2200 2000 1800>,
			<1600 1400 1200 1000 900 800>,
			<700 600 500 400 300 200>,
			<100 0>;
		qcom,lut-data = <6161 5430 5140 4994 4949 4935>,
			<6186 5427 5141 4993 4949 4935>,
			<6201 5425 5142 4993 4950 4935>,
			<6209 5424 5142 4994 4951 4935>,
			<6211 5423 5142 4995 4952 4936>,
			<6211 5422 5142 4997 4953 4937>,
			<6193 5423 5141 4999 4955 4938>,
			<6167 5423 5140 5002 4956 4940>,
			<6151 5424 5142 5005 4958 4941>,
			<6137 5425 5145 5009 4960 4943>,
			<6135 5425 5149 5012 4963 4946>,
			<6149 5420 5153 5016 4966 4947>,
			<6160 5416 5158 5021 4969 4950>,
			<6154 5434 5170 5027 4973 4952>,
			<6136 5463 5183 5034 4977 4955>,
			<6099 5459 5185 5039 4981 4958>,
			<6010 5411 5185 5044 4984 4962>,
			<5962 5374 5185 5049 4987 4966>,
			<5974 5361 5171 5056 4994 4971>,
			<5990 5352 5150 5061 4999 4975>,
			<5988 5343 5134 5054 4999 4975>,
			<5978 5335 5120 5033 4995 4975>,
			<5968 5331 5112 5015 4988 4972>,
			<5952 5329 5107 4997 4967 4953>,
			<5941 5327 5104 4989 4951 4938>,
			<5946 5324 5103 4989 4951 4937>,
			<5962 5321 5102 4990 4950 4938>,
			<5979 5320 5103 4991 4951 4938>,
			<5998 5322 5106 4995 4954 4941>,
			<6018 5323 5110 4999 4958 4944>,
			<6042 5325 5113 5003 4963 4947>,
			<6070 5329 5115 5007 4967 4951>,
			<6106 5339 5117 5012 4972 4956>,
			<6149 5360 5118 5016 4976 4960>,
			<6191 5380 5119 5018 4977 4961>,
			<6233 5396 5127 5018 4974 4955>,
			<6281 5414 5135 5018 4968 4948>,
			<6337 5440 5144 5013 4961 4943>,
			<6402 5472 5152 5005 4953 4939>,
			<6466 5502 5155 5005 4952 4939>,
			<6533 5530 5156 5005 4956 4941>,
			<6606 5551 5159 5005 4956 4941>,
			<6670 5568 5163 5005 4955 4941>,
			<6652 5582 5155 4999 4954 4939>,
			<6551 5574 5143 4991 4947 4934>,
			<6692 5649 5167 5003 4956 4946>,
			<6754 5710 5182 5012 4962 4945>,
			<6831 5768 5204 5024 4970 4962>,
			<6915 5840 5230 5033 4979 4967>,
			<7003 5915 5256 5037 4979 4971>,
			<7095 5992 5258 5021 4964 4954>,
			<7211 6115 5278 5023 4962 4949>,
			<7485 6335 5347 5036 4969 4967>,
			<8340 6657 5439 5064 4986 4973>,
			<8340 6657 5439 5064 4986 4973>,
			<8340 6657 5439 5064 4986 4973>;
	};

};
